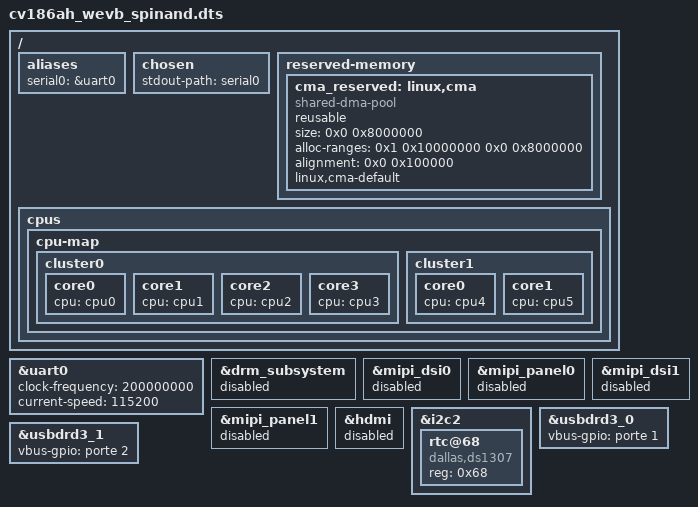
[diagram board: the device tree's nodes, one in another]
/dts-v1/;
#include "soph_base_arm64.dtsi"
//#include "soph_asic_bga.dtsi"
#include "soph_asic_spinand.dtsi"
#include "soph_default_memmap.dtsi"

/ {
	aliases {
		serial0 = &uart0;
	};

	chosen {
		stdout-path = "serial0"; // "serial0:115200n8", no arguments means no re-initialization
	};

	reserved-memory {
		#address-cells = <0x2>;
		#size-cells = <0x2>;
		ranges;

		cma_reserved: linux,cma {
			compatible = "shared-dma-pool";
			reusable;
			size = <0x0 0x8000000>; // 128m for drm
			alloc-ranges = <0x1 0x10000000 0x0 0x8000000>;   // to fix hdmi audio bug
			alignment = <0x0 0x100000>; // 1MB
			linux,cma-default;
		};
	};

	cpus {
		#size-cells = <0x0>;
		#address-cells = <0x1>;

		/delete-node/ cpu-map;
		cpu-map {
			cluster0 {
				core0 {
					cpu = <&cpu0>;
				};
				core1 {
					cpu = <&cpu1>;
				};
				core2 {
					cpu = <&cpu2>;
				};
				core3 {
					cpu = <&cpu3>;
				};
			};

			cluster1 {
				core0 {
					cpu = <&cpu4>;
				};
				core1 {
					cpu = <&cpu5>;
				};
			};
		};
		/delete-node/ cpu@102;
		/delete-node/ cpu@103;
	};

};

&uart0 {
	clock-frequency = <200000000>;
	current-speed = <115200>;
};

&drm_subsystem {
	status = "disable";
};
&mipi_dsi0 {
	status = "disable";
};
&mipi_panel0 {
	status = "disable";
};
&mipi_dsi1 {
	status = "disable";
};
&mipi_panel1 {
	status = "disable";
};
&hdmi {
	status = "disable";
};

&i2c2 {
	rtc@68 {
		compatible = "dallas,ds1307";
		reg = <0x68>;
	};
};

&usbdrd3_0 {
	vbus-gpio = <&porte 1 GPIO_ACTIVE_HIGH>;
};

&usbdrd3_1 {
	vbus-gpio = <&porte 2 GPIO_ACTIVE_HIGH>;
};
